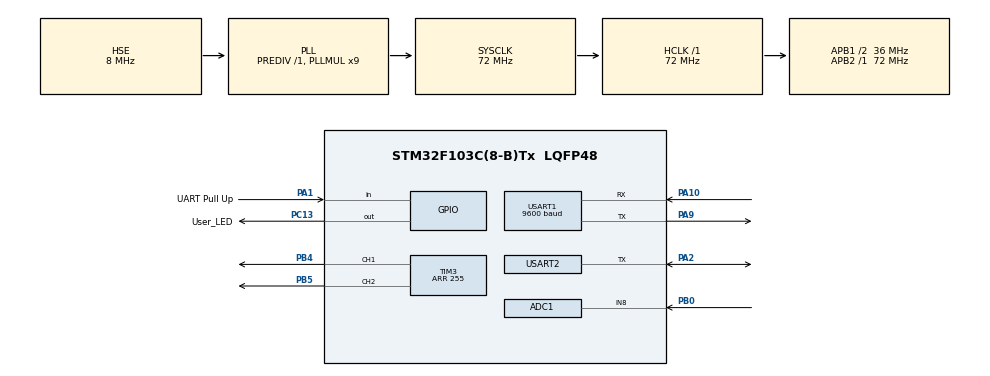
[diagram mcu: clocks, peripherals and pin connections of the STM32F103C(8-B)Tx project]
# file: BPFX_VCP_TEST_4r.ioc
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ADC1.Channel-0\#ChannelRegularConversion=ADC_CHANNEL_8
ADC1.ContinuousConvMode=DISABLE
ADC1.DataAlign=ADC_DATAALIGN_RIGHT
ADC1.DiscontinuousConvMode=DISABLE
ADC1.EnableAnalogWatchDog=false
ADC1.EnableRegularConversion=ENABLE
ADC1.ExternalTrigConv=ADC_EXTERNALTRIGCONV_T2_CC2
ADC1.InjNumberOfConversion=0
ADC1.NbrOfConversion=1
ADC1.NbrOfConversionFlag=1
ADC1.Rank-0\#ChannelRegularConversion=1
ADC1.SamplingTime-0\#ChannelRegularConversion=ADC_SAMPLETIME_1CYCLE_5
ADC1.ScanConvMode=ADC_SCAN_DISABLE
ADC1.master=1
Dma.ADC1.0.Direction=DMA_PERIPH_TO_MEMORY
Dma.ADC1.0.Instance=DMA1_Channel1
Dma.ADC1.0.MemDataAlignment=DMA_MDATAALIGN_HALFWORD
Dma.ADC1.0.MemInc=DMA_MINC_ENABLE
Dma.ADC1.0.Mode=DMA_CIRCULAR
Dma.ADC1.0.PeriphDataAlignment=DMA_PDATAALIGN_HALFWORD
Dma.ADC1.0.PeriphInc=DMA_PINC_DISABLE
Dma.ADC1.0.Priority=DMA_PRIORITY_HIGH
Dma.Request0=ADC1
Mcu.Family=STM32F1
Mcu.Name=STM32F103C(8-B)Tx
Mcu.Package=LQFP48
NVIC.DMA1_Channel1_IRQn=true\:0\:0\:false\:false\:true\:true\:true
NVIC.PriorityGroup=NVIC_PRIORITYGROUP_4
NVIC.USART1_IRQn=true\:2\:0\:true\:false\:true\:true\:true
NVIC.USART2_IRQn=true\:2\:0\:true\:false\:true\:true\:true
PA1.GPIO_Label=UART Pull Up
PA1.GPIO_PuPd=GPIO_PULLUP
PA1.Signal=GPIO_Input
PA10.Mode=Asynchronous
PA10.Signal=USART1_RX
PA13.Mode=Serial_Wire
PA13.Signal=SYS_JTMS-SWDIO
PA14.Mode=Serial_Wire
PA14.Signal=SYS_JTCK-SWCLK
PA2.Mode=Half_duplex(single_wire_mode)
PA2.Signal=USART2_TX
PA9.Mode=Asynchronous
PA9.Signal=USART1_TX
PB0.Signal=ADCx_IN8
PB4.GPIO_Speed=GPIO_SPEED_FREQ_HIGH
PB4.Signal=S_TIM3_CH1
PB5.GPIO_Speed=GPIO_SPEED_FREQ_HIGH
PB5.Signal=S_TIM3_CH2
PC13-TAMPER-RTC.GPIO_Label=User_LED
PC13-TAMPER-RTC.Signal=GPIO_Output
PD0-OSC_IN.Mode=HSE-External-Oscillator
PD0-OSC_IN.Signal=RCC_OSC_IN
PD1-OSC_OUT.Mode=HSE-External-Oscillator
PD1-OSC_OUT.Signal=RCC_OSC_OUT
ProjectManager.HeapSize=0x200
ProjectManager.StackSize=0x400
ProjectManager.TargetToolchain=STM32CubeIDE
RCC.AHBFreq_Value=72000000
RCC.APB1CLKDivider=RCC_HCLK_DIV2
RCC.APB1Freq_Value=36000000
RCC.APB1TimFreq_Value=72000000
RCC.APB2Freq_Value=72000000
RCC.APB2TimFreq_Value=72000000
RCC.HCLKFreq_Value=72000000
RCC.PLLMUL=RCC_PLL_MUL9
RCC.PLLSourceVirtual=RCC_PLLSOURCE_HSE
RCC.SYSCLKFreq_VALUE=72000000
RCC.SYSCLKSource=RCC_SYSCLKSOURCE_PLLCLK
RCC.USBFreq_Value=72000000
SH.ADCx_IN8.0=ADC1_IN8,IN8
SH.S_TIM3_CH1.0=TIM3_CH1,PWM Generation1 CH1
SH.S_TIM3_CH2.0=TIM3_CH2,PWM Generation2 CH2
TIM2.Channel-Output\ Compare2\ No\ Output=TIM_CHANNEL_2
TIM2.CounterMode=TIM_COUNTERMODE_UP
TIM2.OCMode_2=TIM_OCMODE_TOGGLE
TIM2.Period=17
TIM2.TIM_MasterOutputTrigger=TIM_TRGO_OC2REF
TIM2.TIM_MasterSlaveMode=TIM_MASTERSLAVEMODE_ENABLE
TIM3.AutoReloadPreload=TIM_AUTORELOAD_PRELOAD_ENABLE
TIM3.Channel-PWM\ Generation1\ CH1=TIM_CHANNEL_1
TIM3.Channel-PWM\ Generation2\ CH2=TIM_CHANNEL_2
TIM3.CounterMode=TIM_COUNTERMODE_UP
TIM3.Period=255
TIM3.Pulse-PWM\ Generation1\ CH1=127
TIM3.Pulse-PWM\ Generation2\ CH2=127
USART1.BaudRate=9600
USART1.VirtualMode=VM_ASYNC
USART2.BaudRate=9600
USART2.VirtualMode=VM_ASYNC
VP_TIM2_VS_no_output2.Mode=Output Compare2 No Output
board=BPD_VCP_TEST_001

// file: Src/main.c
/* USER CODE BEGIN Header */
/**
  ******************************************************************************
  * @file           : main.c
  * @brief          : Main program body
  ******************************************************************************
  ** This notice applies to any and all portions of this file
  * that are not between comment pairs USER CODE BEGIN and
  * USER CODE END. Other portions of this file, whether
  * inserted by the user or by software development tools
  * are owned by their respective copyright owners.
  *
  * COPYRIGHT(c) 2018 STMicroelectronics
  *
  * Redistribution and use in source and binary forms, with or without modification,
  * are permitted provided that the following conditions are met:
  *   1. Redistributions of source code must retain the above copyright notice,
  *      this list of conditions and the following disclaimer.
  *   2. Redistributions in binary form must reproduce the above copyright notice,
  *      this list of conditions and the following disclaimer in the documentation
  *      and/or other materials provided with the distribution.
  *   3. Neither the name of STMicroelectronics nor the names of its contributors
  *      may be used to endorse or promote products derived from this software
  *      without specific prior written permission.
  *
  * THIS SOFTWARE IS PROVIDED BY THE COPYRIGHT HOLDERS AND CONTRIBUTORS "AS IS"
  * AND ANY EXPRESS OR IMPLIED WARRANTIES, INCLUDING, BUT NOT LIMITED TO, THE
  * IMPLIED WARRANTIES OF MERCHANTABILITY AND FITNESS FOR A PARTICULAR PURPOSE ARE
  * DISCLAIMED. IN NO EVENT SHALL THE COPYRIGHT HOLDER OR CONTRIBUTORS BE LIABLE
  * FOR ANY DIRECT, INDIRECT, INCIDENTAL, SPECIAL, EXEMPLARY, OR CONSEQUENTIAL
  * DAMAGES (INCLUDING, BUT NOT LIMITED TO, PROCUREMENT OF SUBSTITUTE GOODS OR
  * SERVICES; LOSS OF USE, DATA, OR PROFITS; OR BUSINESS INTERRUPTION) HOWEVER
  * CAUSED AND ON ANY THEORY OF LIABILITY, WHETHER IN CONTRACT, STRICT LIABILITY,
  * OR TORT (INCLUDING NEGLIGENCE OR OTHERWISE) ARISING IN ANY WAY OUT OF THE USE
  * OF THIS SOFTWARE, EVEN IF ADVISED OF THE POSSIBILITY OF SUCH DAMAGE.
  *
  ******************************************************************************
  */
/* USER CODE END Header */

#include "main.h"

ADC_HandleTypeDef hadc1;
DMA_HandleTypeDef hdma_adc1;

TIM_HandleTypeDef htim2;
TIM_HandleTypeDef htim3;

UART_HandleTypeDef huart1;
UART_HandleTypeDef huart2;

/* USER CODE BEGIN PV */
/* Private variables ---------------------------------------------------------*/

/* USER CODE END PV */

void SystemClock_Config(void);
static void MX_GPIO_Init(void);
static void MX_DMA_Init(void);
static void MX_ADC1_Init(void);
static void MX_TIM2_Init(void);
static void MX_USART1_UART_Init(void);
static void MX_TIM3_Init(void);
static void MX_USART2_UART_Init(void);
/* USER CODE BEGIN PFP */
/* Private function prototypes -----------------------------------------------*/
void main_cpp();
/* USER CODE END PFP */

int main(void)
{

  /* MCU Configuration--------------------------------------------------------*/

  /* Reset of all peripherals, Initializes the Flash interface and the Systick. */
  HAL_Init();

  /* Configure the system clock */
  SystemClock_Config();

  /* Initialize all configured peripherals */
  MX_GPIO_Init();
  MX_DMA_Init();
  MX_ADC1_Init();
  MX_TIM2_Init();
  MX_USART1_UART_Init();
  MX_TIM3_Init();
  MX_USART2_UART_Init();

  /* Infinite loop */
  /* USER CODE BEGIN WHILE */
//  while (1)
  {
  	main_cpp();
    /* USER CODE END WHILE */

  }
}

void SystemClock_Config(void)
{
  RCC_OscInitTypeDef RCC_OscInitStruct = {0};
  RCC_ClkInitTypeDef RCC_ClkInitStruct = {0};
  RCC_PeriphCLKInitTypeDef PeriphClkInit = {0};

  /** Initializes the CPU, AHB and APB busses clocks
  */
  RCC_OscInitStruct.OscillatorType = RCC_OSCILLATORTYPE_HSE;
  RCC_OscInitStruct.HSEState = RCC_HSE_ON;
  RCC_OscInitStruct.HSEPredivValue = RCC_HSE_PREDIV_DIV1;
  RCC_OscInitStruct.HSIState = RCC_HSI_ON;
  RCC_OscInitStruct.PLL.PLLState = RCC_PLL_ON;
  RCC_OscInitStruct.PLL.PLLSource = RCC_PLLSOURCE_HSE;
  RCC_OscInitStruct.PLL.PLLMUL = RCC_PLL_MUL9;
  if (HAL_RCC_OscConfig(&RCC_OscInitStruct) != HAL_OK)
  {
    Error_Handler();
  }
  /** Initializes the CPU, AHB and APB busses clocks
  */
  RCC_ClkInitStruct.ClockType = RCC_CLOCKTYPE_HCLK|RCC_CLOCKTYPE_SYSCLK
                              |RCC_CLOCKTYPE_PCLK1|RCC_CLOCKTYPE_PCLK2;
  RCC_ClkInitStruct.SYSCLKSource = RCC_SYSCLKSOURCE_PLLCLK;
  RCC_ClkInitStruct.AHBCLKDivider = RCC_SYSCLK_DIV1;
  RCC_ClkInitStruct.APB1CLKDivider = RCC_HCLK_DIV2;
  RCC_ClkInitStruct.APB2CLKDivider = RCC_HCLK_DIV1;

  if (HAL_RCC_ClockConfig(&RCC_ClkInitStruct, FLASH_LATENCY_2) != HAL_OK)
  {
    Error_Handler();
  }
  PeriphClkInit.PeriphClockSelection = RCC_PERIPHCLK_ADC;
  PeriphClkInit.AdcClockSelection = RCC_ADCPCLK2_DIV2;
  if (HAL_RCCEx_PeriphCLKConfig(&PeriphClkInit) != HAL_OK)
  {
    Error_Handler();
  }
}

static void MX_ADC1_Init(void)
{

  ADC_ChannelConfTypeDef sConfig = {0};

  /** Common config
  */
  hadc1.Instance = ADC1;
  hadc1.Init.ScanConvMode = ADC_SCAN_DISABLE;
  hadc1.Init.ContinuousConvMode = DISABLE;
  hadc1.Init.DiscontinuousConvMode = DISABLE;
  hadc1.Init.ExternalTrigConv = ADC_EXTERNALTRIGCONV_T2_CC2;
  hadc1.Init.DataAlign = ADC_DATAALIGN_RIGHT;
  hadc1.Init.NbrOfConversion = 1;
  if (HAL_ADC_Init(&hadc1) != HAL_OK)
  {
    Error_Handler();
  }
  /** Configure Regular Channel
  */
  sConfig.Channel = ADC_CHANNEL_8;
  sConfig.Rank = ADC_REGULAR_RANK_1;
  sConfig.SamplingTime = ADC_SAMPLETIME_1CYCLE_5;
  if (HAL_ADC_ConfigChannel(&hadc1, &sConfig) != HAL_OK)
  {
    Error_Handler();
  }

}

static void MX_TIM2_Init(void)
{

  TIM_MasterConfigTypeDef sMasterConfig = {0};
  TIM_OC_InitTypeDef sConfigOC = {0};

  htim2.Instance = TIM2;
  htim2.Init.Prescaler = 0;
  htim2.Init.CounterMode = TIM_COUNTERMODE_UP;
  htim2.Init.Period = 17;
  htim2.Init.ClockDivision = TIM_CLOCKDIVISION_DIV1;
  htim2.Init.AutoReloadPreload = TIM_AUTORELOAD_PRELOAD_DISABLE;
  if (HAL_TIM_OC_Init(&htim2) != HAL_OK)
  {
    Error_Handler();
  }
  sMasterConfig.MasterOutputTrigger = TIM_TRGO_OC2REF;
  sMasterConfig.MasterSlaveMode = TIM_MASTERSLAVEMODE_ENABLE;
  if (HAL_TIMEx_MasterConfigSynchronization(&htim2, &sMasterConfig) != HAL_OK)
  {
    Error_Handler();
  }
  sConfigOC.OCMode = TIM_OCMODE_TOGGLE;
  sConfigOC.Pulse = 0;
  sConfigOC.OCPolarity = TIM_OCPOLARITY_HIGH;
  sConfigOC.OCFastMode = TIM_OCFAST_DISABLE;
  if (HAL_TIM_OC_ConfigChannel(&htim2, &sConfigOC, TIM_CHANNEL_2) != HAL_OK)
  {
    Error_Handler();
  }

}

static void MX_TIM3_Init(void)
{

  TIM_MasterConfigTypeDef sMasterConfig = {0};
  TIM_OC_InitTypeDef sConfigOC = {0};

  htim3.Instance = TIM3;
  htim3.Init.Prescaler = 0;
  htim3.Init.CounterMode = TIM_COUNTERMODE_UP;
  htim3.Init.Period = 255;
  htim3.Init.ClockDivision = TIM_CLOCKDIVISION_DIV1;
  htim3.Init.AutoReloadPreload = TIM_AUTORELOAD_PRELOAD_ENABLE;
  if (HAL_TIM_PWM_Init(&htim3) != HAL_OK)
  {
    Error_Handler();
  }
  sMasterConfig.MasterOutputTrigger = TIM_TRGO_RESET;
  sMasterConfig.MasterSlaveMode = TIM_MASTERSLAVEMODE_DISABLE;
  if (HAL_TIMEx_MasterConfigSynchronization(&htim3, &sMasterConfig) != HAL_OK)
  {
    Error_Handler();
  }
  sConfigOC.OCMode = TIM_OCMODE_PWM1;
  sConfigOC.Pulse = 127;
  sConfigOC.OCPolarity = TIM_OCPOLARITY_HIGH;
  sConfigOC.OCFastMode = TIM_OCFAST_DISABLE;
  if (HAL_TIM_PWM_ConfigChannel(&htim3, &sConfigOC, TIM_CHANNEL_1) != HAL_OK)
  {
    Error_Handler();
  }
  if (HAL_TIM_PWM_ConfigChannel(&htim3, &sConfigOC, TIM_CHANNEL_2) != HAL_OK)
  {
    Error_Handler();
  }
  HAL_TIM_MspPostInit(&htim3);

}

static void MX_USART1_UART_Init(void)
{

  huart1.Instance = USART1;
  huart1.Init.BaudRate = 9600;
  huart1.Init.WordLength = UART_WORDLENGTH_8B;
  huart1.Init.StopBits = UART_STOPBITS_1;
  huart1.Init.Parity = UART_PARITY_NONE;
  huart1.Init.Mode = UART_MODE_TX_RX;
  huart1.Init.HwFlowCtl = UART_HWCONTROL_NONE;
  huart1.Init.OverSampling = UART_OVERSAMPLING_16;
  if (HAL_UART_Init(&huart1) != HAL_OK)
  {
    Error_Handler();
  }

}

static void MX_USART2_UART_Init(void)
{

  huart2.Instance = USART2;
  huart2.Init.BaudRate = 9600;
  huart2.Init.WordLength = UART_WORDLENGTH_8B;
  huart2.Init.StopBits = UART_STOPBITS_1;
  huart2.Init.Parity = UART_PARITY_NONE;
  huart2.Init.Mode = UART_MODE_TX_RX;
  huart2.Init.HwFlowCtl = UART_HWCONTROL_NONE;
  huart2.Init.OverSampling = UART_OVERSAMPLING_16;
  if (HAL_HalfDuplex_Init(&huart2) != HAL_OK)
  {
    Error_Handler();
  }

}

static void MX_DMA_Init(void)
{
  /* DMA controller clock enable */
  __HAL_RCC_DMA1_CLK_ENABLE();

  /* DMA interrupt init */
  /* DMA1_Channel1_IRQn interrupt configuration */
  HAL_NVIC_SetPriority(DMA1_Channel1_IRQn, 0, 0);
  HAL_NVIC_EnableIRQ(DMA1_Channel1_IRQn);

}

static void MX_GPIO_Init(void)
{
  GPIO_InitTypeDef GPIO_InitStruct = {0};

  /* GPIO Ports Clock Enable */
  __HAL_RCC_GPIOC_CLK_ENABLE();
  __HAL_RCC_GPIOD_CLK_ENABLE();
  __HAL_RCC_GPIOA_CLK_ENABLE();
  __HAL_RCC_GPIOB_CLK_ENABLE();

  /*Configure GPIO pin Output Level */
  HAL_GPIO_WritePin(User_LED_GPIO_Port, User_LED_Pin, GPIO_PIN_RESET);

  /*Configure GPIO pin : User_LED_Pin */
  GPIO_InitStruct.Pin = User_LED_Pin;
  GPIO_InitStruct.Mode = GPIO_MODE_OUTPUT_PP;
  GPIO_InitStruct.Pull = GPIO_NOPULL;
  GPIO_InitStruct.Speed = GPIO_SPEED_FREQ_LOW;
  HAL_GPIO_Init(User_LED_GPIO_Port, &GPIO_InitStruct);

  /*Configure GPIO pin : UART_Pull_Up_Pin */
  GPIO_InitStruct.Pin = UART_Pull_Up_Pin;
  GPIO_InitStruct.Mode = GPIO_MODE_INPUT;
  GPIO_InitStruct.Pull = GPIO_PULLUP;
  HAL_GPIO_Init(UART_Pull_Up_GPIO_Port, &GPIO_InitStruct);

}

void Error_Handler(void)
{
  while(1)
  {
  }
}

/************************ (C) COPYRIGHT STMicroelectronics *****END OF FILE****/
